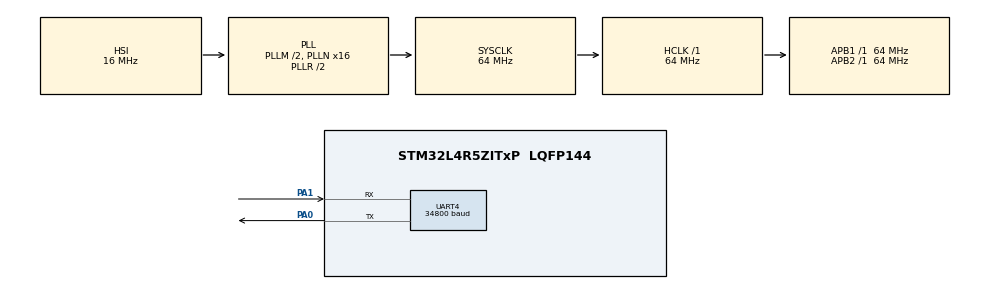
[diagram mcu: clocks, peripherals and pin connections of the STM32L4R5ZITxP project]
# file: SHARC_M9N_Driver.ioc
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Dma.Request0=UART4_RX
Dma.Request1=UART4_TX
Dma.UART4_RX.0.Direction=DMA_PERIPH_TO_MEMORY
Dma.UART4_RX.0.EventEnable=DISABLE
Dma.UART4_RX.0.Instance=DMA1_Channel1
Dma.UART4_RX.0.MemDataAlignment=DMA_MDATAALIGN_BYTE
Dma.UART4_RX.0.MemInc=DMA_MINC_ENABLE
Dma.UART4_RX.0.Mode=DMA_CIRCULAR
Dma.UART4_RX.0.PeriphDataAlignment=DMA_PDATAALIGN_BYTE
Dma.UART4_RX.0.PeriphInc=DMA_PINC_DISABLE
Dma.UART4_RX.0.Polarity=HAL_DMAMUX_REQUEST_GEN_RISING
Dma.UART4_RX.0.Priority=DMA_PRIORITY_LOW
Dma.UART4_RX.0.RequestNumber=1
Dma.UART4_RX.0.SignalID=NONE
Dma.UART4_RX.0.SyncEnable=DISABLE
Dma.UART4_RX.0.SyncPolarity=HAL_DMAMUX_SYNC_NO_EVENT
Dma.UART4_RX.0.SyncRequestNumber=1
Dma.UART4_RX.0.SyncSignalID=NONE
Dma.UART4_TX.1.Direction=DMA_MEMORY_TO_PERIPH
Dma.UART4_TX.1.EventEnable=DISABLE
Dma.UART4_TX.1.Instance=DMA1_Channel2
Dma.UART4_TX.1.MemDataAlignment=DMA_MDATAALIGN_BYTE
Dma.UART4_TX.1.MemInc=DMA_MINC_ENABLE
Dma.UART4_TX.1.Mode=DMA_NORMAL
Dma.UART4_TX.1.PeriphDataAlignment=DMA_PDATAALIGN_BYTE
Dma.UART4_TX.1.PeriphInc=DMA_PINC_DISABLE
Dma.UART4_TX.1.Polarity=HAL_DMAMUX_REQUEST_GEN_RISING
Dma.UART4_TX.1.Priority=DMA_PRIORITY_LOW
Dma.UART4_TX.1.RequestNumber=1
Dma.UART4_TX.1.SignalID=NONE
Dma.UART4_TX.1.SyncEnable=DISABLE
Dma.UART4_TX.1.SyncPolarity=HAL_DMAMUX_SYNC_NO_EVENT
Dma.UART4_TX.1.SyncRequestNumber=1
Dma.UART4_TX.1.SyncSignalID=NONE
Mcu.Family=STM32L4
Mcu.Name=STM32L4R5ZITxP
Mcu.Package=LQFP144
NVIC.DMA1_Channel1_IRQn=true\:6\:0\:true\:false\:true\:false\:true\:true
NVIC.DMA1_Channel2_IRQn=true\:7\:0\:true\:false\:true\:false\:true\:true
NVIC.PriorityGroup=NVIC_PRIORITYGROUP_4
NVIC.UART4_IRQn=true\:7\:0\:true\:false\:true\:true\:true\:true
PA0.Mode=Asynchronous
PA0.Signal=UART4_TX
PA1.Mode=Asynchronous
PA1.Signal=UART4_RX
PA13\ (JTMS/SWDIO).Mode=Serial_Wire
PA13\ (JTMS/SWDIO).Signal=SYS_JTMS-SWDIO
PA14\ (JTCK/SWCLK).Mode=Serial_Wire
PA14\ (JTCK/SWCLK).Signal=SYS_JTCK-SWCLK
ProjectManager.HeapSize=0x200
ProjectManager.StackSize=0x400
ProjectManager.TargetToolchain=Makefile
RCC.ADCFreq_Value=192000000
RCC.AHBFreq_Value=64000000
RCC.APB1Freq_Value=64000000
RCC.APB1TimFreq_Value=64000000
RCC.APB2Freq_Value=64000000
RCC.APB2TimFreq_Value=64000000
RCC.CortexFreq_Value=64000000
RCC.HCLKFreq_Value=64000000
RCC.HSE_VALUE=8000000
RCC.HSI48_VALUE=48000000
RCC.HSI_VALUE=16000000
RCC.LSE_VALUE=32768
RCC.MSI_VALUE=4000000
RCC.PLLM1=2
RCC.PLLN=16
RCC.PLLSAI1N=24
RCC.PLLSourceVirtual=RCC_PLLSOURCE_HSI
RCC.SYSCLKFreq_VALUE=64000000
RCC.SYSCLKSource=RCC_SYSCLKSOURCE_PLLCLK
RCC.USBFreq_Value=192000000
RCC.VCOOutputFreq_Value=128000000
UART4.BaudRate=34800
UART4.FIFOMode=FIFOMODE_ENABLE
UART4.RXFIFOThreshold=RXFIFO_THRESHOLD_HALFFULL
board=NUCLEO-L4R5ZI-P

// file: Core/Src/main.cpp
/* USER CODE BEGIN Header */
/**
  ******************************************************************************
  * @file           : main.c
  * @brief          : Main program body
  ******************************************************************************
  * @attention
  *
  * Copyright (c) 2022 STMicroelectronics.
  * All rights reserved.
  *
  * This software is licensed under terms that can be found in the LICENSE file
  * in the root directory of this software component.
  * If no LICENSE file comes with this software, it is provided AS-IS.
  *
  ******************************************************************************
  */
/* USER CODE END Header */
#include "main.h"

/* USER CODE BEGIN Includes */
#include "M9N_STM32.hpp"
#include "M9N_C_API.hpp"
/* USER CODE END Includes */

UART_HandleTypeDef huart4;
DMA_HandleTypeDef hdma_uart4_rx;
DMA_HandleTypeDef hdma_uart4_tx;

/* USER CODE BEGIN PV */
GPS_Data_t gpsDataLive = {0};
/* USER CODE END PV */

void SystemClock_Config(void);
static void MX_GPIO_Init(void);
static void MX_DMA_Init(void);
static void MX_UART4_Init(void);

/* USER CODE BEGIN 0 */
int main(){
	HAL_Init();
	SystemClock_Config();
	MX_GPIO_Init();
	MX_DMA_Init();
	MX_UART4_Init();

	GPS_Init();

	while(true){
		HAL_Delay(100);
		GPS_Update();
	}
}
/* USER CODE END 0 */

void SystemClock_Config(void)
{
  RCC_OscInitTypeDef RCC_OscInitStruct = {0};
  RCC_ClkInitTypeDef RCC_ClkInitStruct = {0};

  /** Configure the main internal regulator output voltage
  */
  if (HAL_PWREx_ControlVoltageScaling(PWR_REGULATOR_VOLTAGE_SCALE1) != HAL_OK)
  {
    Error_Handler();
  }

  /** Initializes the RCC Oscillators according to the specified parameters
  * in the RCC_OscInitTypeDef structure.
  */
  RCC_OscInitStruct.OscillatorType = RCC_OSCILLATORTYPE_HSI;
  RCC_OscInitStruct.HSIState = RCC_HSI_ON;
  RCC_OscInitStruct.HSICalibrationValue = RCC_HSICALIBRATION_DEFAULT;
  RCC_OscInitStruct.PLL.PLLState = RCC_PLL_ON;
  RCC_OscInitStruct.PLL.PLLSource = RCC_PLLSOURCE_HSI;
  RCC_OscInitStruct.PLL.PLLM = 2;
  RCC_OscInitStruct.PLL.PLLN = 16;
  RCC_OscInitStruct.PLL.PLLP = RCC_PLLP_DIV2;
  RCC_OscInitStruct.PLL.PLLQ = RCC_PLLQ_DIV2;
  RCC_OscInitStruct.PLL.PLLR = RCC_PLLR_DIV2;
  if (HAL_RCC_OscConfig(&RCC_OscInitStruct) != HAL_OK)
  {
    Error_Handler();
  }

  /** Initializes the CPU, AHB and APB buses clocks
  */
  RCC_ClkInitStruct.ClockType = RCC_CLOCKTYPE_HCLK|RCC_CLOCKTYPE_SYSCLK
                              |RCC_CLOCKTYPE_PCLK1|RCC_CLOCKTYPE_PCLK2;
  RCC_ClkInitStruct.SYSCLKSource = RCC_SYSCLKSOURCE_PLLCLK;
  RCC_ClkInitStruct.AHBCLKDivider = RCC_SYSCLK_DIV1;
  RCC_ClkInitStruct.APB1CLKDivider = RCC_HCLK_DIV1;
  RCC_ClkInitStruct.APB2CLKDivider = RCC_HCLK_DIV1;

  if (HAL_RCC_ClockConfig(&RCC_ClkInitStruct, FLASH_LATENCY_3) != HAL_OK)
  {
    Error_Handler();
  }
}

static void MX_UART4_Init(void)
{

  huart4.Instance = UART4;
  huart4.Init.BaudRate = 38400;
  huart4.Init.WordLength = UART_WORDLENGTH_8B;
  huart4.Init.StopBits = UART_STOPBITS_1;
  huart4.Init.Parity = UART_PARITY_NONE;
  huart4.Init.Mode = UART_MODE_TX_RX;
  huart4.Init.HwFlowCtl = UART_HWCONTROL_NONE;
  huart4.Init.OverSampling = UART_OVERSAMPLING_16;
  huart4.Init.OneBitSampling = UART_ONE_BIT_SAMPLE_DISABLE;
  huart4.Init.ClockPrescaler = UART_PRESCALER_DIV1;
  huart4.AdvancedInit.AdvFeatureInit = UART_ADVFEATURE_NO_INIT;
  if (HAL_UART_Init(&huart4) != HAL_OK)
  {
    Error_Handler();
  }
  if (HAL_UARTEx_SetTxFifoThreshold(&huart4, UART_TXFIFO_THRESHOLD_1_8) != HAL_OK)
  {
    Error_Handler();
  }
  if (HAL_UARTEx_SetRxFifoThreshold(&huart4, UART_RXFIFO_THRESHOLD_1_2) != HAL_OK)
  {
    Error_Handler();
  }
  if (HAL_UARTEx_EnableFifoMode(&huart4) != HAL_OK)
  {
    Error_Handler();
  }

}

static void MX_DMA_Init(void)
{

  /* DMA controller clock enable */
  __HAL_RCC_DMAMUX1_CLK_ENABLE();
  __HAL_RCC_DMA1_CLK_ENABLE();

  /* DMA interrupt init */
  /* DMA1_Channel1_IRQn interrupt configuration */
  HAL_NVIC_SetPriority(DMA1_Channel1_IRQn, 6, 0);
  HAL_NVIC_EnableIRQ(DMA1_Channel1_IRQn);
  /* DMA1_Channel2_IRQn interrupt configuration */
  HAL_NVIC_SetPriority(DMA1_Channel2_IRQn, 7, 0);
  HAL_NVIC_EnableIRQ(DMA1_Channel2_IRQn);

}

static void MX_GPIO_Init(void)
{

  /* GPIO Ports Clock Enable */
  __HAL_RCC_GPIOA_CLK_ENABLE();

}

void Error_Handler(void)
{
  __disable_irq();
  while (1)
  {
  }
}
